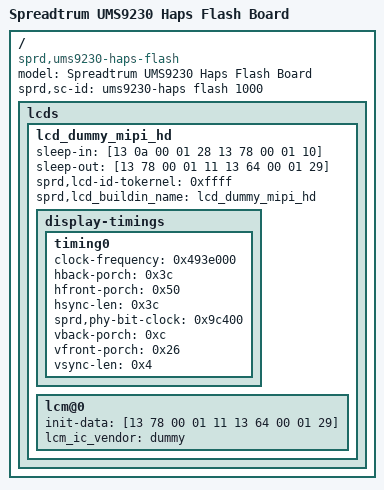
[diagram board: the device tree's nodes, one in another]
/dts-v1/;

/ {
	compatible = "sprd,ums9230-haps-flash";
	model = "Spreadtrum UMS9230 Haps Flash Board";
	sprd,sc-id = "ums9230-haps flash 1000";

	__fixups__ {
		chosen = "/fragment@0:target:0";
	};

	__local_fixups__ {

		fragment {

			__overlay__ {

				lcds {

					lcd_nt35596_boe_mipi_fhd {

						display-timings {
							native-mode = <0x0>;
						};
					};

					lcd_nt35695_truly_mipi_fhd {

						display-timings {
							native-mode = <0x0>;
						};
					};
				};
			};
		};
	};

	__symbols__ {
		lcd_dummy_mipi_hd = "/lcds/lcd_dummy_mipi_hd";
		lcd_dummy_timing0 = "/lcds/lcd_dummy_mipi_hd/display-timings/timing0";
		lcd_nt35596_boe_mipi_fhd = "/fragment/__overlay__/lcds/lcd_nt35596_boe_mipi_fhd";
		lcd_nt35695_truly_mipi_fhd = "/fragment/__overlay__/lcds/lcd_nt35695_truly_mipi_fhd";
		nt35596_boe_timing0 = "/fragment/__overlay__/lcds/lcd_nt35596_boe_mipi_fhd/display-timings/timing0";
		nt35695_truly_timing0 = "/fragment/__overlay__/lcds/lcd_nt35695_truly_mipi_fhd/display-timings/timing0";
	};

	fragment {
		target-path = [2f 00];

		__overlay__ {

			lcds {

				lcd_nt35596_boe_mipi_fhd {
					phandle = <0x3>;
					sprd,dsi-color-format = "rgb888";
					sprd,dsi-lane-number = <0x4>;
					sprd,dsi-work-mode = <0x1>;
					sprd,esd-check-enable = <0x1>;
					sprd,esd-check-mode = <0x1>;
					sprd,esd-check-period = <0x3e8>;
					sprd,height-mm = <0x79>;
					sprd,initial-command = [23 00 00 02 ff ee 23 0a 00 02 18 40 23 14 00 02 18 00 23 00 00 02 ff 01 23 00 00 02 fb 01 23 00 00 02 00 01 23 00 00 02 01 55 23 00 00 02 02 40 23 00 00 02 05 40 23 00 00 02 06 94 23 00 00 02 07 94 23 00 00 02 08 0c 23 00 00 02 11 19 23 00 00 02 12 19 23 00 00 02 13 03 23 00 00 02 14 94 23 00 00 02 15 15 23 00 00 02 16 15 23 00 00 02 6d 22 23 00 00 02 0b af 23 00 00 02 0c af 23 00 00 02 0e ab 23 00 00 02 0f a4 23 00 00 02 58 82 23 00 00 02 59 02 23 00 00 02 5a 02 23 00 00 02 5b 02 23 00 00 02 5c 82 23 00 00 02 5d 82 23 00 00 02 5e 02 23 00 00 02 5f 02 23 00 00 02 75 00 23 00 00 02 76 00 23 00 00 02 77 00 23 00 00 02 78 11 23 00 00 02 79 00 23 00 00 02 7a 30 23 00 00 02 7b 00 23 00 00 02 7c 4a 23 00 00 02 7d 00 23 00 00 02 7e 62 23 00 00 02 7f 00 23 00 00 02 80 78 23 00 00 02 81 00 23 00 00 02 82 8c 23 00 00 02 83 00 23 00 00 02 84 9e 23 00 00 02 85 00 23 00 00 02 86 ae 23 00 00 02 87 00 23 00 00 02 88 e4 23 00 00 02 89 01 23 00 00 02 8a 0e 23 00 00 02 8b 01 23 00 00 02 8c 4c 23 00 00 02 8d 01 23 00 00 02 8e 7b 23 00 00 02 8f 01 23 00 00 02 90 c2 23 00 00 02 91 01 23 00 00 02 92 fb 23 00 00 02 93 01 23 00 00 02 94 fc 23 00 00 02 95 02 23 00 00 02 96 34 23 00 00 02 97 02 23 00 00 02 98 79 23 00 00 02 99 02 23 00 00 02 9a a4 23 00 00 02 9b 02 23 00 00 02 9c dd 23 00 00 02 9d 03 23 00 00 02 9e 05 23 00 00 02 9f 03 23 00 00 02 a0 39 23 00 00 02 a2 03 23 00 00 02 a3 48 23 00 00 02 a4 03 23 00 00 02 a5 58 23 00 00 02 a6 03 23 00 00 02 a7 6a 23 00 00 02 a9 03 23 00 00 02 aa 7f 23 00 00 02 ab 03 23 00 00 02 ac 98 23 00 00 02 ad 03 23 00 00 02 ae b7 23 00 00 02 af 03 23 00 00 02 b0 d7 23 00 00 02 b1 03 23 00 00 02 b2 ff 23 00 00 02 b3 00 23 00 00 02 b4 00 23 00 00 02 b5 00 23 00 00 02 b6 11 23 00 00 02 b7 00 23 00 00 02 b8 30 23 00 00 02 b9 00 23 00 00 02 ba 4a 23 00 00 02 bb 00 23 00 00 02 bc 62 23 00 00 02 bd 00 23 00 00 02 be 78 23 00 00 02 bf 00 23 00 00 02 c0 8c 23 00 00 02 c1 00 23 00 00 02 c2 9e 23 00 00 02 c3 00 23 00 00 02 c4 ae 23 00 00 02 c5 00 23 00 00 02 c6 e4 23 00 00 02 c7 01 23 00 00 02 c8 0e 23 00 00 02 c9 01 23 00 00 02 ca 4c 23 00 00 02 cb 01 23 00 00 02 cc 7b 23 00 00 02 cd 01 23 00 00 02 ce c2 23 00 00 02 cf 01 23 00 00 02 d0 fb 23 00 00 02 d1 01 23 00 00 02 d2 fc 23 00 00 02 d3 02 23 00 00 02 d4 34 23 00 00 02 d5 02 23 00 00 02 d6 79 23 00 00 02 d7 02 23 00 00 02 d8 a4 23 00 00 02 d9 02 23 00 00 02 da dd 23 00 00 02 db 03 23 00 00 02 dc 05 23 00 00 02 dd 03 23 00 00 02 de 39 23 00 00 02 df 03 23 00 00 02 e0 48 23 00 00 02 e1 03 23 00 00 02 e2 58 23 00 00 02 e3 03 23 00 00 02 e4 6a 23 00 00 02 e5 03 23 00 00 02 e6 7f 23 00 00 02 e7 03 23 00 00 02 e8 98 23 00 00 02 e9 03 23 00 00 02 ea b7 23 00 00 02 eb 03 23 00 00 02 ec d7 23 00 00 02 ed 03 23 00 00 02 ee ff 23 00 00 02 ef 00 23 00 00 02 f0 00 23 00 00 02 f1 00 23 00 00 02 f2 11 23 00 00 02 f3 00 23 00 00 02 f4 30 23 00 00 02 f5 00 23 00 00 02 f6 4a 23 00 00 02 f7 00 23 00 00 02 f8 62 23 00 00 02 f9 00 23 00 00 02 fa 78 23 00 00 02 ff 02 23 00 00 02 fb 01 23 00 00 02 00 00 23 00 00 02 01 8c 23 00 00 02 02 00 23 00 00 02 03 9e 23 00 00 02 04 00 23 00 00 02 05 ae 23 00 00 02 06 00 23 00 00 02 07 e4 23 00 00 02 08 01 23 00 00 02 09 0e 23 00 00 02 0a 01 23 00 00 02 0b 4c 23 00 00 02 0c 01 23 00 00 02 0d 7b 23 00 00 02 0e 01 23 00 00 02 0f c2 23 00 00 02 10 01 23 00 00 02 11 fb 23 00 00 02 12 01 23 00 00 02 13 fc 23 00 00 02 14 02 23 00 00 02 15 34 23 00 00 02 16 02 23 00 00 02 17 79 23 00 00 02 18 02 23 00 00 02 19 a4 23 00 00 02 1a 02 23 00 00 02 1b dd 23 00 00 02 1c 03 23 00 00 02 1d 05 23 00 00 02 1e 03 23 00 00 02 1f 39 23 00 00 02 20 03 23 00 00 02 21 48 23 00 00 02 22 03 23 00 00 02 23 58 23 00 00 02 24 03 23 00 00 02 25 6a 23 00 00 02 26 03 23 00 00 02 27 7f 23 00 00 02 28 03 23 00 00 02 29 98 23 00 00 02 2a 03 23 00 00 02 2b b7 23 00 00 02 2d 03 23 00 00 02 2f d7 23 00 00 02 30 03 23 00 00 02 31 ff 23 00 00 02 32 00 23 00 00 02 33 00 23 00 00 02 34 00 23 00 00 02 35 11 23 00 00 02 36 00 23 00 00 02 37 30 23 00 00 02 38 00 23 00 00 02 39 4a 23 00 00 02 3a 00 23 00 00 02 3b 62 23 00 00 02 3d 00 23 00 00 02 3f 78 23 00 00 02 40 00 23 00 00 02 41 8c 23 00 00 02 42 00 23 00 00 02 43 9e 23 00 00 02 44 00 23 00 00 02 45 ae 23 00 00 02 46 00 23 00 00 02 47 e4 23 00 00 02 48 01 23 00 00 02 49 0e 23 00 00 02 4a 01 23 00 00 02 4b 4c 23 00 00 02 4c 01 23 00 00 02 4d 7b 23 00 00 02 4e 01 23 00 00 02 4f c2 23 00 00 02 50 01 23 00 00 02 51 fb 23 00 00 02 52 01 23 00 00 02 53 fc 23 00 00 02 54 02 23 00 00 02 55 34 23 00 00 02 56 02 23 00 00 02 58 79 23 00 00 02 59 02 23 00 00 02 5a a4 23 00 00 02 5b 02 23 00 00 02 5c dd 23 00 00 02 5d 03 23 00 00 02 5e 05 23 00 00 02 5f 03 23 00 00 02 60 39 23 00 00 02 61 03 23 00 00 02 62 48 23 00 00 02 63 03 23 00 00 02 64 58 23 00 00 02 65 03 23 00 00 02 66 6a 23 00 00 02 67 03 23 00 00 02 68 7f 23 00 00 02 69 03 23 00 00 02 6a 98 23 00 00 02 6b 03 23 00 00 02 6c b7 23 00 00 02 6d 03 23 00 00 02 6e d7 23 00 00 02 6f 03 23 00 00 02 70 ff 23 00 00 02 71 00 23 00 00 02 72 00 23 00 00 02 73 00 23 00 00 02 74 11 23 00 00 02 75 00 23 00 00 02 76 30 23 00 00 02 77 00 23 00 00 02 78 4a 23 00 00 02 79 00 23 00 00 02 7a 62 23 00 00 02 7b 00 23 00 00 02 7c 78 23 00 00 02 7d 00 23 00 00 02 7e 8c 23 00 00 02 7f 00 23 00 00 02 80 9e 23 00 00 02 81 00 23 00 00 02 82 ae 23 00 00 02 83 00 23 00 00 02 84 e4 23 00 00 02 85 01 23 00 00 02 86 0e 23 00 00 02 87 01 23 00 00 02 88 4c 23 00 00 02 89 01 23 00 00 02 8a 7b 23 00 00 02 8b 01 23 00 00 02 8c c2 23 00 00 02 8d 01 23 00 00 02 8e fb 23 00 00 02 8f 01 23 00 00 02 90 fc 23 00 00 02 91 02 23 00 00 02 92 34 23 00 00 02 93 02 23 00 00 02 94 79 23 00 00 02 95 02 23 00 00 02 96 a4 23 00 00 02 97 02 23 00 00 02 98 dd 23 00 00 02 99 03 23 00 00 02 9a 05 23 00 00 02 9b 03 23 00 00 02 9c 39 23 00 00 02 9d 03 23 00 00 02 9e 48 23 00 00 02 9f 03 23 00 00 02 a0 58 23 00 00 02 a2 03 23 00 00 02 a3 6a 23 00 00 02 a4 03 23 00 00 02 a5 7f 23 00 00 02 a6 03 23 00 00 02 a7 98 23 00 00 02 a9 03 23 00 00 02 aa b7 23 00 00 02 ab 03 23 00 00 02 ac d7 23 00 00 02 ad 03 23 00 00 02 ae ff 23 00 00 02 af 00 23 00 00 02 b0 00 23 00 00 02 b1 00 23 00 00 02 b2 11 23 00 00 02 b3 00 23 00 00 02 b4 30 23 00 00 02 b5 00 23 00 00 02 b6 4a 23 00 00 02 b7 00 23 00 00 02 b8 62 23 00 00 02 b9 00 23 00 00 02 ba 78 23 00 00 02 bb 00 23 00 00 02 bc 8c 23 00 00 02 bd 00 23 00 00 02 be 9e 23 00 00 02 bf 00 23 00 00 02 c0 ae 23 00 00 02 c1 00 23 00 00 02 c2 e4 23 00 00 02 c3 01 23 00 00 02 c4 0e 23 00 00 02 c5 01 23 00 00 02 c6 4c 23 00 00 02 c7 01 23 00 00 02 c8 7b 23 00 00 02 c9 01 23 00 00 02 ca c2 23 00 00 02 cb 01 23 00 00 02 cc fb 23 00 00 02 cd 01 23 00 00 02 ce fc 23 00 00 02 cf 02 23 00 00 02 d0 34 23 00 00 02 d1 02 23 00 00 02 d2 79 23 00 00 02 d3 02 23 00 00 02 d4 a4 23 00 00 02 d5 02 23 00 00 02 d6 dd 23 00 00 02 d7 03 23 00 00 02 d8 05 23 00 00 02 d9 03 23 00 00 02 da 39 23 00 00 02 db 03 23 00 00 02 dc 48 23 00 00 02 dd 03 23 00 00 02 de 58 23 00 00 02 df 03 23 00 00 02 e0 6a 23 00 00 02 e1 03 23 00 00 02 e2 7f 23 00 00 02 e3 03 23 00 00 02 e4 98 23 00 00 02 e5 03 23 00 00 02 e6 b7 23 00 00 02 e7 03 23 00 00 02 e8 d7 23 00 00 02 e9 03 23 00 00 02 ea ff 23 00 00 02 ff 05 23 00 00 02 fb 01 23 00 00 02 00 00 23 00 00 02 01 01 23 00 00 02 02 0b 23 00 00 02 03 0c 23 00 00 02 04 00 23 00 00 02 05 03 23 00 00 02 06 00 23 00 00 02 07 04 23 00 00 02 08 00 23 00 00 02 09 00 23 00 00 02 0a 00 23 00 00 02 0b 00 23 00 00 02 0c 00 23 00 00 02 0d 17 23 00 00 02 0e 15 23 00 00 02 0f 13 23 00 00 02 10 00 23 00 00 02 11 01 23 00 00 02 12 0b 23 00 00 02 13 0c 23 00 00 02 14 00 23 00 00 02 15 03 23 00 00 02 16 00 23 00 00 02 17 04 23 00 00 02 18 00 23 00 00 02 19 00 23 00 00 02 1a 00 23 00 00 02 1b 00 23 00 00 02 1c 00 23 00 00 02 1d 17 23 00 00 02 1e 15 23 00 00 02 1f 13 23 00 00 02 20 09 23 00 00 02 21 02 23 00 00 02 22 00 23 00 00 02 23 00 23 00 00 02 24 00 23 00 00 02 25 3d 23 00 00 02 29 38 23 00 00 02 2a 2b 23 00 00 02 2f 02 23 00 00 02 30 01 23 00 00 02 31 49 23 00 00 02 32 23 23 00 00 02 33 01 23 00 00 02 34 05 23 00 00 02 35 74 23 00 00 02 36 00 23 00 00 02 37 2d 23 00 00 02 38 08 23 00 00 02 92 94 23 00 00 02 5b 00 23 00 00 02 5f 1d 23 00 00 02 63 00 23 00 00 02 67 04 23 00 00 02 6c 55 23 00 00 02 7a 00 23 00 00 02 7b a2 23 00 00 02 7c d8 23 00 00 02 7d 50 23 00 00 02 7e 0a 23 00 00 02 7f 1c 23 00 00 02 81 06 23 00 00 02 82 02 23 00 00 02 84 03 23 00 00 02 85 05 23 00 00 02 c5 20 23 00 00 02 80 00 23 00 00 02 83 00 23 00 00 02 93 08 23 00 00 02 94 0a 23 00 00 02 8a 33 23 00 00 02 a4 0f 23 00 00 02 9b 0f 23 00 00 02 9d b0 23 00 00 02 e7 83 23 00 00 02 e3 02 23 00 00 02 ff 00 23 00 00 02 d2 03 23 00 00 02 d3 24 23 00 00 02 d4 20 23 00 00 02 35 00 23 00 00 02 ba 03 13 78 00 01 11 13 64 00 01 29];
					sprd,phy-bit-clock = <0xf4240>;
					sprd,phy-escape-clock = <0x4e20>;
					sprd,reset-off-sequence = <0x0 0x14>;
					sprd,reset-on-sequence = <0x1 0x5 0x0 0x5 0x1 0x5 0x0 0x5 0x1 0x14>;
					sprd,sleep-in-command = <0x130a0001 0x28137800 0x110230a 0x24f01>;
					sprd,sleep-out-command = [13 78 00 01 11 13 64 00 01 29];
					sprd,width-mm = <0x44>;

					display-timings {
						native-mode = <0x1>;

						timing0 {
							clock-frequency = <0x927c000>;
							hactive = <0x438>;
							hback-porch = <0x10>;
							hfront-porch = <0xb0>;
							hsync-len = <0xa>;
							phandle = <0x1>;
							vactive = <0x780>;
							vback-porch = <0x20>;
							vfront-porch = <0x20>;
							vsync-len = <0x4>;
						};
					};
				};

				lcd_nt35695_truly_mipi_fhd {
					phandle = <0x4>;
					sprd,dsi-color-format = "rgb888";
					sprd,dsi-lane-number = <0x4>;
					sprd,dsi-work-mode = <0x1>;
					sprd,esd-check-enable = <0x1>;
					sprd,esd-check-mode = <0x1>;
					sprd,esd-check-period = <0x7d0>;
					sprd,height-mm = <0x79>;
					sprd,initial-command = [23 00 00 02 ff 20 23 00 00 02 00 01 23 00 00 02 01 55 23 00 00 02 02 45 23 00 00 02 03 55 23 00 00 02 05 50 23 00 00 02 06 4a 23 00 00 02 07 24 23 00 00 02 08 0c 23 00 00 02 0b 87 23 00 00 02 0c 87 23 00 00 02 0e b0 23 00 00 02 0f b3 23 00 00 02 11 25 23 00 00 02 12 10 23 00 00 02 13 03 23 00 00 02 14 4a 23 00 00 02 15 12 23 00 00 02 16 12 23 00 00 02 30 01 23 00 00 02 58 82 23 00 00 02 59 00 23 00 00 02 5a 02 23 00 00 02 5b 00 23 00 00 02 5c 82 23 00 00 02 5d 82 23 00 00 02 5e 02 23 00 00 02 5f 02 23 00 00 02 72 31 23 00 00 02 fb 01 23 00 00 02 75 00 23 00 00 02 76 00 23 00 00 02 77 00 23 00 00 02 78 06 23 00 00 02 79 00 23 00 00 02 7a 1a 23 00 00 02 7b 00 23 00 00 02 7c 37 23 00 00 02 7d 00 23 00 00 02 7e 5a 23 00 00 02 7f 00 23 00 00 02 80 75 23 00 00 02 81 00 23 00 00 02 82 8d 23 00 00 02 83 00 23 00 00 02 84 a0 23 00 00 02 85 00 23 00 00 02 86 b1 23 00 00 02 87 00 23 00 00 02 88 e4 23 00 00 02 89 01 23 00 00 02 8a 07 23 00 00 02 8b 01 23 00 00 02 8c 36 23 00 00 02 8d 01 23 00 00 02 8e 5d 23 00 00 02 8f 01 23 00 00 02 90 a9 23 00 00 02 91 01 23 00 00 02 92 e1 23 00 00 02 93 01 23 00 00 02 94 e3 23 00 00 02 95 02 23 00 00 02 96 11 23 00 00 02 97 02 23 00 00 02 98 54 23 00 00 02 99 02 23 00 00 02 9a 7f 23 00 00 02 9b 02 23 00 00 02 9c bd 23 00 00 02 9d 02 23 00 00 02 9e e5 23 00 00 02 9f 03 23 00 00 02 a0 1b 23 00 00 02 a2 03 23 00 00 02 a3 25 23 00 00 02 a4 03 23 00 00 02 a5 28 23 00 00 02 a6 03 23 00 00 02 a7 3a 23 00 00 02 a9 03 23 00 00 02 aa 5d 23 00 00 02 ab 03 23 00 00 02 ac a4 23 00 00 02 ad 03 23 00 00 02 ae c1 23 00 00 02 af 03 23 00 00 02 b0 d3 23 00 00 02 b1 03 23 00 00 02 b2 d8 23 00 00 02 b3 00 23 00 00 02 b4 00 23 00 00 02 b5 00 23 00 00 02 b6 06 23 00 00 02 b7 00 23 00 00 02 b8 1a 23 00 00 02 b9 00 23 00 00 02 ba 37 23 00 00 02 bb 00 23 00 00 02 bc 5a 23 00 00 02 bd 00 23 00 00 02 be 75 23 00 00 02 bf 00 23 00 00 02 c0 8d 23 00 00 02 c1 00 23 00 00 02 c2 a0 23 00 00 02 c3 00 23 00 00 02 c4 b1 23 00 00 02 c5 00 23 00 00 02 c6 e4 23 00 00 02 c7 01 23 00 00 02 c8 07 23 00 00 02 c9 01 23 00 00 02 ca 36 23 00 00 02 cb 01 23 00 00 02 cc 5d 23 00 00 02 cd 01 23 00 00 02 ce a9 23 00 00 02 cf 01 23 00 00 02 d0 e1 23 00 00 02 d1 01 23 00 00 02 d2 e3 23 00 00 02 d3 02 23 00 00 02 d4 11 23 00 00 02 d5 02 23 00 00 02 d6 54 23 00 00 02 d7 02 23 00 00 02 d8 7f 23 00 00 02 d9 02 23 00 00 02 da bd 23 00 00 02 db 02 23 00 00 02 dc e5 23 00 00 02 dd 03 23 00 00 02 de 1b 23 00 00 02 df 03 23 00 00 02 e0 25 23 00 00 02 e1 03 23 00 00 02 e2 28 23 00 00 02 e3 03 23 00 00 02 e4 3a 23 00 00 02 e5 03 23 00 00 02 e6 5d 23 00 00 02 e7 03 23 00 00 02 e8 a4 23 00 00 02 e9 03 23 00 00 02 ea c1 23 00 00 02 eb 03 23 00 00 02 ec d3 23 00 00 02 ed 03 23 00 00 02 ee d8 23 00 00 02 ef 00 23 00 00 02 f0 ba 23 00 00 02 f1 00 23 00 00 02 f2 c1 23 00 00 02 f3 00 23 00 00 02 f4 d1 23 00 00 02 f5 00 23 00 00 02 f6 de 23 00 00 02 f7 00 23 00 00 02 f8 e7 23 00 00 02 f9 00 23 00 00 02 fa f0 23 00 00 02 ff 21 23 00 00 02 00 00 23 00 00 02 01 fa 23 00 00 02 02 01 23 00 00 02 03 03 23 00 00 02 04 01 23 00 00 02 05 0e 23 00 00 02 06 01 23 00 00 02 07 33 23 00 00 02 08 01 23 00 00 02 09 4c 23 00 00 02 0a 01 23 00 00 02 0b 6d 23 00 00 02 0c 01 23 00 00 02 0d 8a 23 00 00 02 0e 01 23 00 00 02 0f c0 23 00 00 02 10 01 23 00 00 02 11 ef 23 00 00 02 12 01 23 00 00 02 13 f1 23 00 00 02 14 02 23 00 00 02 15 20 23 00 00 02 16 02 23 00 00 02 17 63 23 00 00 02 18 02 23 00 00 02 19 91 23 00 00 02 1a 02 23 00 00 02 1b cf 23 00 00 02 1c 02 23 00 00 02 1d f9 23 00 00 02 1e 03 23 00 00 02 1f 31 23 00 00 02 20 03 23 00 00 02 21 3d 23 00 00 02 22 03 23 00 00 02 23 40 23 00 00 02 24 03 23 00 00 02 25 51 23 00 00 02 26 03 23 00 00 02 27 71 23 00 00 02 28 03 23 00 00 02 29 85 23 00 00 02 2a 03 23 00 00 02 2b ab 23 00 00 02 2d 03 23 00 00 02 2f d6 23 00 00 02 30 03 23 00 00 02 31 d8 23 00 00 02 32 00 23 00 00 02 33 ba 23 00 00 02 34 00 23 00 00 02 35 c1 23 00 00 02 36 00 23 00 00 02 37 d1 23 00 00 02 38 00 23 00 00 02 39 de 23 00 00 02 3a 00 23 00 00 02 3b e7 23 00 00 02 3d 00 23 00 00 02 3f f0 23 00 00 02 40 00 23 00 00 02 41 fa 23 00 00 02 42 01 23 00 00 02 43 03 23 00 00 02 44 01 23 00 00 02 45 0e 23 00 00 02 46 01 23 00 00 02 47 33 23 00 00 02 48 01 23 00 00 02 49 4c 23 00 00 02 4a 01 23 00 00 02 4b 6d 23 00 00 02 4c 01 23 00 00 02 4d 8a 23 00 00 02 4e 01 23 00 00 02 4f c0 23 00 00 02 50 01 23 00 00 02 51 ef 23 00 00 02 52 01 23 00 00 02 53 f1 23 00 00 02 54 02 23 00 00 02 55 20 23 00 00 02 56 02 23 00 00 02 58 63 23 00 00 02 59 02 23 00 00 02 5a 91 23 00 00 02 5b 02 23 00 00 02 5c cf 23 00 00 02 5d 02 23 00 00 02 5e f9 23 00 00 02 5f 03 23 00 00 02 60 31 23 00 00 02 61 03 23 00 00 02 62 3d 23 00 00 02 63 03 23 00 00 02 64 40 23 00 00 02 65 03 23 00 00 02 66 51 23 00 00 02 67 03 23 00 00 02 68 71 23 00 00 02 69 03 23 00 00 02 6a 85 23 00 00 02 6b 03 23 00 00 02 6c ab 23 00 00 02 6d 03 23 00 00 02 6e d6 23 00 00 02 6f 03 23 00 00 02 70 d8 23 00 00 02 71 00 23 00 00 02 72 a7 23 00 00 02 73 00 23 00 00 02 74 ae 23 00 00 02 75 00 23 00 00 02 76 bd 23 00 00 02 77 00 23 00 00 02 78 ca 23 00 00 02 79 00 23 00 00 02 7a d4 23 00 00 02 7b 00 23 00 00 02 7c dd 23 00 00 02 7d 00 23 00 00 02 7e e6 23 00 00 02 7f 00 23 00 00 02 80 ef 23 00 00 02 81 00 23 00 00 02 82 f9 23 00 00 02 83 01 23 00 00 02 84 1d 23 00 00 02 85 01 23 00 00 02 86 36 23 00 00 02 87 01 23 00 00 02 88 5b 23 00 00 02 89 01 23 00 00 02 8a 79 23 00 00 02 8b 01 23 00 00 02 8c ba 23 00 00 02 8d 01 23 00 00 02 8e ea 23 00 00 02 8f 01 23 00 00 02 90 ed 23 00 00 02 91 02 23 00 00 02 92 1b 23 00 00 02 93 02 23 00 00 02 94 5f 23 00 00 02 95 02 23 00 00 02 96 8a 23 00 00 02 97 02 23 00 00 02 98 cc 23 00 00 02 99 02 23 00 00 02 9a fb 23 00 00 02 9b 03 23 00 00 02 9c 61 23 00 00 02 9d 03 23 00 00 02 9e af 23 00 00 02 9f 03 23 00 00 02 a0 c6 23 00 00 02 a2 03 23 00 00 02 a3 cc 23 00 00 02 a4 03 23 00 00 02 a5 ce 23 00 00 02 a6 03 23 00 00 02 a7 d2 23 00 00 02 a9 03 23 00 00 02 aa d4 23 00 00 02 ab 03 23 00 00 02 ac d7 23 00 00 02 ad 03 23 00 00 02 ae d8 23 00 00 02 af 00 23 00 00 02 b0 a7 23 00 00 02 b1 00 23 00 00 02 b2 ae 23 00 00 02 b3 00 23 00 00 02 b4 bd 23 00 00 02 b5 00 23 00 00 02 b6 ca 23 00 00 02 b7 00 23 00 00 02 b8 d4 23 00 00 02 b9 00 23 00 00 02 ba dd 23 00 00 02 bb 00 23 00 00 02 bc e6 23 00 00 02 bd 00 23 00 00 02 be ef 23 00 00 02 bf 00 23 00 00 02 c0 f9 23 00 00 02 c1 01 23 00 00 02 c2 1d 23 00 00 02 c3 01 23 00 00 02 c4 36 23 00 00 02 c5 01 23 00 00 02 c6 5b 23 00 00 02 c7 01 23 00 00 02 c8 79 23 00 00 02 c9 01 23 00 00 02 ca ba 23 00 00 02 cb 01 23 00 00 02 cc ea 23 00 00 02 cd 01 23 00 00 02 ce ed 23 00 00 02 cf 02 23 00 00 02 d0 1b 23 00 00 02 d1 02 23 00 00 02 d2 5f 23 00 00 02 d3 02 23 00 00 02 d4 8a 23 00 00 02 d5 02 23 00 00 02 d6 cc 23 00 00 02 d7 02 23 00 00 02 d8 fb 23 00 00 02 d9 03 23 00 00 02 da 61 23 00 00 02 db 03 23 00 00 02 dc af 23 00 00 02 dd 03 23 00 00 02 de c6 23 00 00 02 df 03 23 00 00 02 e0 cc 23 00 00 02 e1 03 23 00 00 02 e2 ce 23 00 00 02 e3 03 23 00 00 02 e4 d2 23 00 00 02 e5 03 23 00 00 02 e6 d4 23 00 00 02 e7 03 23 00 00 02 e8 d7 23 00 00 02 e9 03 23 00 00 02 ea d8 23 00 00 02 ff 24 23 00 00 02 00 01 23 00 00 02 01 0b 23 00 00 02 02 0c 23 00 00 02 03 09 23 00 00 02 04 0a 23 00 00 02 05 1c 23 00 00 02 06 10 23 00 00 02 07 00 23 00 00 02 08 1c 23 00 00 02 09 00 23 00 00 02 0a 00 23 00 00 02 0b 00 23 00 00 02 0c 00 23 00 00 02 0d 13 23 00 00 02 0e 15 23 00 00 02 0f 17 23 00 00 02 10 01 23 00 00 02 11 0b 23 00 00 02 12 0c 23 00 00 02 13 09 23 00 00 02 14 0a 23 00 00 02 15 1c 23 00 00 02 16 10 23 00 00 02 17 10 23 00 00 02 18 1c 23 00 00 02 19 00 23 00 00 02 1a 00 23 00 00 02 1b 00 23 00 00 02 1c 00 23 00 00 02 1d 13 23 00 00 02 1e 15 23 00 00 02 1f 17 23 00 00 02 20 00 23 00 00 02 21 03 23 00 00 02 22 01 23 00 00 02 23 4a 23 00 00 02 24 4a 23 00 00 02 25 6d 23 00 00 02 26 40 23 00 00 02 27 40 23 00 00 02 bd 20 23 00 00 02 b6 22 23 00 00 02 b7 24 23 00 00 02 b8 07 23 00 00 02 b9 07 23 00 00 02 c1 6d 23 00 00 02 be 07 23 00 00 02 bf 07 23 00 00 02 29 d8 23 00 00 02 2a 2a 23 00 00 02 4b 04 23 00 00 02 4c 12 23 00 00 02 4d 00 23 00 00 02 4e 22 23 00 00 02 4f 22 23 00 00 02 50 00 23 00 00 02 51 61 23 00 00 02 52 01 23 00 00 02 53 08 23 00 00 02 56 08 23 00 00 02 54 8a 23 00 00 02 58 8a 23 00 00 02 55 6d 23 00 00 02 5b 43 23 00 00 02 5c 00 23 00 00 02 5f 73 23 00 00 02 60 73 23 00 00 02 63 22 23 00 00 02 64 00 23 00 00 02 67 08 23 00 00 02 68 04 23 00 00 02 7a 80 23 00 00 02 7b 91 23 00 00 02 7c d8 23 00 00 02 7d 60 23 00 00 02 75 20 23 00 00 02 7f 20 23 00 00 02 74 10 23 00 00 02 7e 10 23 00 00 02 93 06 23 00 00 02 94 06 23 00 00 02 b3 00 23 00 00 02 b4 00 23 00 00 02 b5 00 23 00 00 02 78 00 23 00 00 02 79 00 23 00 00 02 80 00 23 00 00 02 83 00 23 00 00 02 84 04 23 00 00 02 8a 33 23 00 00 02 9b 0f 23 00 00 02 8b f0 23 00 00 02 e3 00 23 00 00 02 fb 01 23 00 00 02 ec 00 23 00 00 02 ff 10 29 00 00 04 3b 03 24 20 23 00 00 02 35 00 23 00 00 02 bb 03 29 00 00 03 51 ff 00 23 00 00 02 53 2c 23 00 00 02 55 00 13 50 00 01 11 13 14 00 01 29];
					sprd,phy-bit-clock = <0xf4240>;
					sprd,phy-escape-clock = <0x4e20>;
					sprd,reset-off-sequence = <0x1 0x5>;
					sprd,reset-on-sequence = <0x1 0x5 0x0 0x5 0x1 0x14>;
					sprd,sleep-in-command = [13 01 00 01 00 13 0a 00 01 28 13 78 00 01 10 23 0a 00 02 4f 01];
					sprd,sleep-out-command = [13 50 00 01 11 13 14 00 01 29];
					sprd,width-mm = <0x44>;

					display-timings {
						native-mode = <0x2>;

						timing0 {
							clock-frequency = <0x927c000>;
							hactive = <0x438>;
							hback-porch = <0x10>;
							hfront-porch = <0xb0>;
							hsync-len = <0xa>;
							phandle = <0x2>;
							vactive = <0x780>;
							vback-porch = <0x20>;
							vfront-porch = <0x20>;
							vsync-len = <0x4>;
						};
					};
				};
			};
		};
	};

	fragment@0 {
		target = <0xffffffff>;

		__overlay__ {
			bootargs_ext = "androidboot.hardware=ums9230_haps_flash androidboot.dtbo_idx=0 androidboot.boot_devices=soc/soc:ap-apb/201d0000.sdio";
		};
	};

	lcds {

		lcd_dummy_mipi_hd {
			phandle = <0x5>;
			sleep-in = [13 0a 00 01 28 13 78 00 01 10];
			sleep-out = [13 78 00 01 11 13 64 00 01 29];
			sprd,lcd-id-tokernel = <0xffff>;
			sprd,lcd_buildin_name = "lcd_dummy_mipi_hd";

			display-timings {

				timing0 {
					clock-frequency = <0x493e000>;
					hback-porch = <0x3c>;
					hfront-porch = <0x50>;
					hsync-len = <0x3c>;
					phandle = <0x6>;
					sprd,phy-bit-clock = <0x9c400>;
					vback-porch = <0xc>;
					vfront-porch = <0x26>;
					vsync-len = <0x4>;
				};
			};

			lcm@0 {
				init-data = [13 78 00 01 11 13 64 00 01 29];
				lcm_ic_vendor = "dummy";
			};
		};
	};
};
